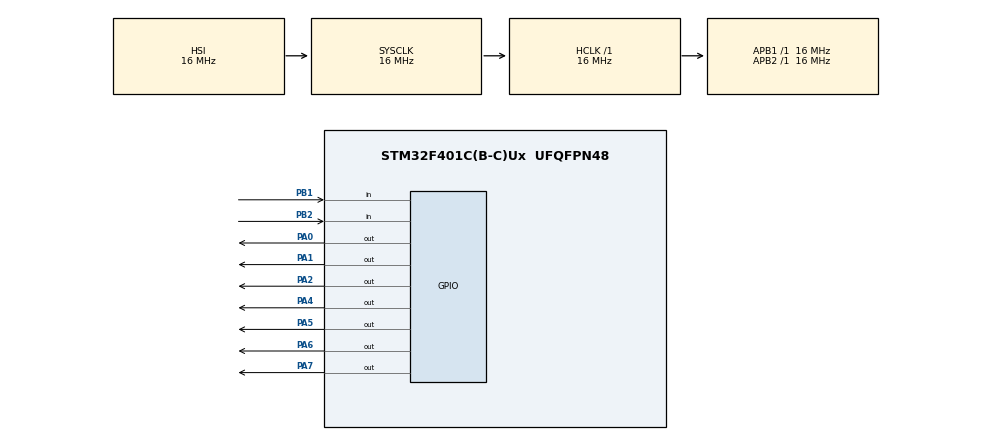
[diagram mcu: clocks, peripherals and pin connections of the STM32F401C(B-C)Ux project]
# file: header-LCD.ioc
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Mcu.Family=STM32F4
RCC.CortexFreq_Value=16000000
ProjectManager.StackSize=0x400
PA0-WKUP.Signal=GPIO_Output
ProjectManager.TargetToolchain=MDK-ARM V5.27
PB1.GPIO_PuPd=GPIO_PULLUP
RCC.LSE_VALUE=32768
PA1.Signal=GPIO_Output
RCC.AHBFreq_Value=16000000
PA5.Signal=GPIO_Output
RCC.HSE_VALUE=25000000
PB2.Signal=GPIO_Input
board=custom
RCC.VCOOutputFreq_Value=192000000
RCC.APB2Freq_Value=16000000
Mcu.Name=STM32F401C(B-C)Ux
PB2.GPIO_PuPd=GPIO_PULLUP
PA2.Signal=GPIO_Output
PA4.Signal=GPIO_Output
RCC.SYSCLKFreq_VALUE=16000000
Mcu.Package=UFQFPN48
PB1.Signal=GPIO_Input
PA6.Signal=GPIO_Output
ProjectManager.HeapSize=0x200
RCC.HSI_VALUE=16000000
NVIC.PriorityGroup=NVIC_PRIORITYGROUP_4
RCC.APB1Freq_Value=16000000
PA7.Signal=GPIO_Output

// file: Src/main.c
/* USER CODE BEGIN Header */
/**
  ******************************************************************************
  * @file           : main.c
  * @brief          : Main program body
  ******************************************************************************
  * @attention
  *
  * <h2><center>&copy; Copyright (c) 2021 STMicroelectronics.
  * All rights reserved.</center></h2>
  *
  * This software component is licensed by ST under BSD 3-Clause license,
  * the "License"; You may not use this file except in compliance with the
  * License. You may obtain a copy of the License at:
  *                        opensource.org/licenses/BSD-3-Clause
  *
  ******************************************************************************
  */
/* USER CODE END Header */
#include "main.h"

/* USER CODE BEGIN Includes */
#include "stlcd.h"
#include "stdio.h"
/* USER CODE END Includes */

/* USER CODE BEGIN PV */
 signed char i=0;
 unsigned char h,m,s,ah,am;
 char t[12];
/* USER CODE END PV */

void SystemClock_Config(void);
static void MX_GPIO_Init(void);

int main(void)
{

  /* MCU Configuration--------------------------------------------------------*/

  /* Reset of all peripherals, Initializes the Flash interface and the Systick. */
  HAL_Init();

  /* Configure the system clock */
  SystemClock_Config();

  /* Initialize all configured peripherals */
  MX_GPIO_Init();
  /* USER CODE BEGIN 2 */
	lcd_init();
  /* USER CODE END 2 */
	lcd_gotoxy(7,0);
	lcd_puts("AI");
	lcd_gotoxy(6,1);
	lcd_puts("2100");
  /* Infinite loop */
  while (1)
  {

  }
}

void SystemClock_Config(void)
{
  RCC_OscInitTypeDef RCC_OscInitStruct = {0};
  RCC_ClkInitTypeDef RCC_ClkInitStruct = {0};

  /** Configure the main internal regulator output voltage
  */
  __HAL_RCC_PWR_CLK_ENABLE();
  __HAL_PWR_VOLTAGESCALING_CONFIG(PWR_REGULATOR_VOLTAGE_SCALE2);
  /** Initializes the RCC Oscillators according to the specified parameters
  * in the RCC_OscInitTypeDef structure.
  */
  RCC_OscInitStruct.OscillatorType = RCC_OSCILLATORTYPE_HSI;
  RCC_OscInitStruct.HSIState = RCC_HSI_ON;
  RCC_OscInitStruct.HSICalibrationValue = RCC_HSICALIBRATION_DEFAULT;
  RCC_OscInitStruct.PLL.PLLState = RCC_PLL_NONE;
  if (HAL_RCC_OscConfig(&RCC_OscInitStruct) != HAL_OK)
  {
    Error_Handler();
  }
  /** Initializes the CPU, AHB and APB buses clocks
  */
  RCC_ClkInitStruct.ClockType = RCC_CLOCKTYPE_HCLK|RCC_CLOCKTYPE_SYSCLK
                              |RCC_CLOCKTYPE_PCLK1|RCC_CLOCKTYPE_PCLK2;
  RCC_ClkInitStruct.SYSCLKSource = RCC_SYSCLKSOURCE_HSI;
  RCC_ClkInitStruct.AHBCLKDivider = RCC_SYSCLK_DIV1;
  RCC_ClkInitStruct.APB1CLKDivider = RCC_HCLK_DIV1;
  RCC_ClkInitStruct.APB2CLKDivider = RCC_HCLK_DIV1;

  if (HAL_RCC_ClockConfig(&RCC_ClkInitStruct, FLASH_LATENCY_0) != HAL_OK)
  {
    Error_Handler();
  }
}

static void MX_GPIO_Init(void)
{
  GPIO_InitTypeDef GPIO_InitStruct = {0};

  /* GPIO Ports Clock Enable */
  __HAL_RCC_GPIOA_CLK_ENABLE();
  __HAL_RCC_GPIOB_CLK_ENABLE();

  /*Configure GPIO pin Output Level */
  HAL_GPIO_WritePin(GPIOA, GPIO_PIN_0|GPIO_PIN_1|GPIO_PIN_2|GPIO_PIN_4
                          |GPIO_PIN_5|GPIO_PIN_6|GPIO_PIN_7, GPIO_PIN_RESET);

  /*Configure GPIO pins : PA0 PA1 PA2 PA4
                           PA5 PA6 PA7 */
  GPIO_InitStruct.Pin = GPIO_PIN_0|GPIO_PIN_1|GPIO_PIN_2|GPIO_PIN_4
                          |GPIO_PIN_5|GPIO_PIN_6|GPIO_PIN_7;
  GPIO_InitStruct.Mode = GPIO_MODE_OUTPUT_PP;
  GPIO_InitStruct.Pull = GPIO_NOPULL;
  GPIO_InitStruct.Speed = GPIO_SPEED_FREQ_LOW;
  HAL_GPIO_Init(GPIOA, &GPIO_InitStruct);

  /*Configure GPIO pins : PB1 PB2 */
  GPIO_InitStruct.Pin = GPIO_PIN_1|GPIO_PIN_2;
  GPIO_InitStruct.Mode = GPIO_MODE_INPUT;
  GPIO_InitStruct.Pull = GPIO_PULLUP;
  HAL_GPIO_Init(GPIOB, &GPIO_InitStruct);

}

void Error_Handler(void)
{
  __disable_irq();
  while (1)
  {
  }
}

/************************ (C) COPYRIGHT STMicroelectronics *****END OF FILE****/
